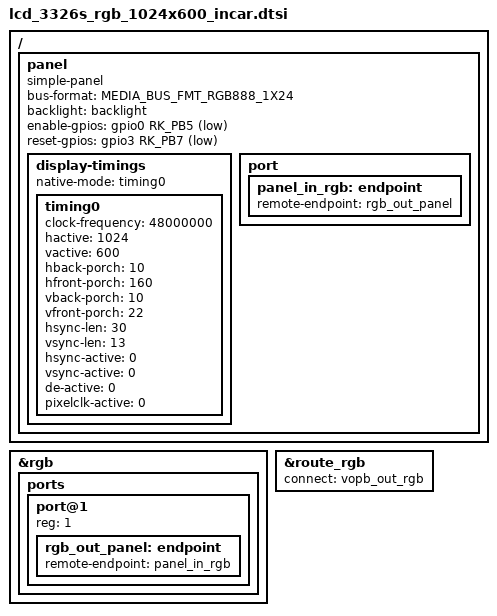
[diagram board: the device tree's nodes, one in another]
/*
* incar rgb lcd
*/
/ {
	status = "okay";

	panel {
	  status = "okay";
		compatible ="simple-panel";
		bus-format = <MEDIA_BUS_FMT_RGB888_1X24>;
		backlight = <&backlight>;
		enable-gpios = <&gpio0 RK_PB5 GPIO_ACTIVE_LOW>;
		reset-gpios = <&gpio3 RK_PB7 GPIO_ACTIVE_LOW>;

		display-timings {
			native-mode = <&timing0>;
			timing0: timing0 {
			clock-frequency = <48000000>;
			hactive = <1024>;
			vactive = <600>;
			hback-porch = <10>;
			hfront-porch = <160>;
			vback-porch = <10>;
			vfront-porch = <22>;
			hsync-len = <30>;
			vsync-len = <13>;
				hsync-active = <0>;
				vsync-active = <0>;
				de-active = <0>;
				pixelclk-active = <0>;
			};
		};

		port {
			panel_in_rgb: endpoint {
				remote-endpoint = <&rgb_out_panel>;
			};
		};
	};
};

&rgb {
	status = "okay";

	ports {
		port@1 {
			reg = <1>;

			rgb_out_panel: endpoint {
				remote-endpoint = <&panel_in_rgb>;
			};
		};
	};
};
&route_rgb {
	connect = <&vopb_out_rgb>;
	status = "okay";
};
